# SAM9X60 device description
Architecture: ARM926EJS; Family: SAM9; Series: SAM9X
Registers are 32-bit, read-write, no defined reset value unless marked. A register's access mark holds for its fields unless they carry their own. Offsets are from the block's base; [hi:lo] are bit positions; lines under a group give offsets from that group; {n}, {i} and the like mark numbered series.

## PMECC — Programmable Multibit Error Correction Code Controller
Instances: PMECC 0xFFFFE000
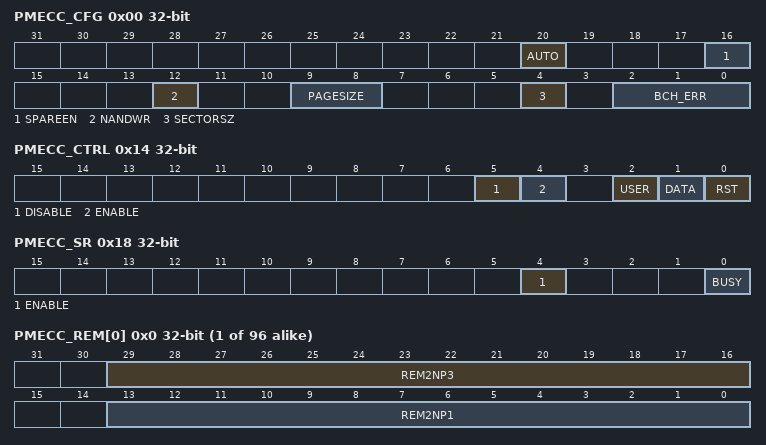
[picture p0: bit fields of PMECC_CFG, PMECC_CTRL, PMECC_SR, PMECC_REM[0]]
0x00 PMECC_CFG — PMECC Configuration Register
  [20] AUTO — Automatic Mode Enable
  [16] SPAREEN — Spare Enable
  [12] NANDWR — NAND Write Access
  [9:8] PAGESIZE — Number of Sectors in the Page
    0=PAGESIZE_1SEC (1 sector for main area (512 or 1024 bytes)); 1=PAGESIZE_2SEC (2 sectors for main area (1024 or 2048 bytes)); 2=PAGESIZE_4SEC (4 sectors for main area (2048 or 4096 bytes)); 3=PAGESIZE_8SEC (8 errors for main area (4096 or 8192 bytes))
  [4] SECTORSZ — Sector Size
  [2:0] BCH_ERR — Error Correct Capability
    0=2 errors; 1=4 errors; 2=8 errors; 3=12 errors; 4=24 errors
0x04 PMECC_SAREA — PMECC Spare Area Size Register
  [8:0] SPARESIZE — Spare Area Size
0x08 PMECC_SADDR — PMECC Start Address Register
  [8:0] STARTADDR — ECC Area Start Address (byte oriented address)
0x0C PMECC_EADDR — PMECC End Address Register
  [8:0] ENDADDR — ECC Area End Address (byte oriented address)
0x10 PMECC_CLK — PMECC Clock Control Register
  [2:0] CLKCTRL — Clock Control Register
0x14 PMECC_CTRL wo — PMECC Control Register
  [5] DISABLE — PMECC Module Disable
  [4] ENABLE — PMECC Module Enable
  [2] USER — Start a User Mode Phase
  [1] DATA — Start a Data Phase
  [0] RST — Reset the PMECC Module
0x18 PMECC_SR ro — PMECC Status Register
  [4] ENABLE — PMECC Module Status
  [0] BUSY — The Kernel of the PMECC is Busy
0x1C PMECC_IER wo — PMECC Interrupt Enable register
  [0] ERRIE — Error Interrupt Enable
0x20 PMECC_IDR wo — PMECC Interrupt Disable Register
  [0] ERRID — Error Interrupt Disable
0x24 PMECC_IMR ro — PMECC Interrupt Mask Register
  [0] ERRIM — Error Interrupt Mask
0x28 PMECC_ISR ro — PMECC Interrupt Status Register
  [7:0] ERRIS — Error Interrupt Status
{0x40+0x40*i} PMECC_ECC[{i}] (i=0..7) group
  {0x0+4j} PMECC_ECC[{j}] (j=0..10) ro — PMECC ECC 0 Register (sec_num = 0)
    [31:0] ECC — BCH Redundancy
{0x240+0x40*i} PMECC_REM[{i}] (i=0..7) group
  {0x0+4j} PMECC_REM[{j}] (j=0..11) ro — PMECC REM 0 Register (sec_num = 0)
    [29:16] REM2NP3 — BCH Remainder 2 * N + 3
    [13:0] REM2NP1 — BCH Remainder 2 * N + 1
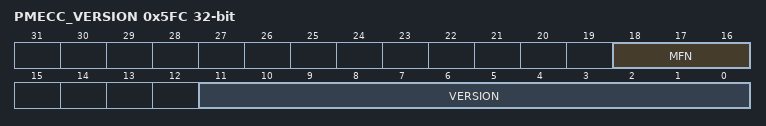
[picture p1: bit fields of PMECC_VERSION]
0x5FC PMECC_VERSION ro
  [18:16] MFN — Metal Fix Number
  [11:0] VERSION — Version of the Hardware Module

## PMERRLOC — Programmable Multibit ECC Error Location
Instances: PMERRLOC 0xFFFFE600
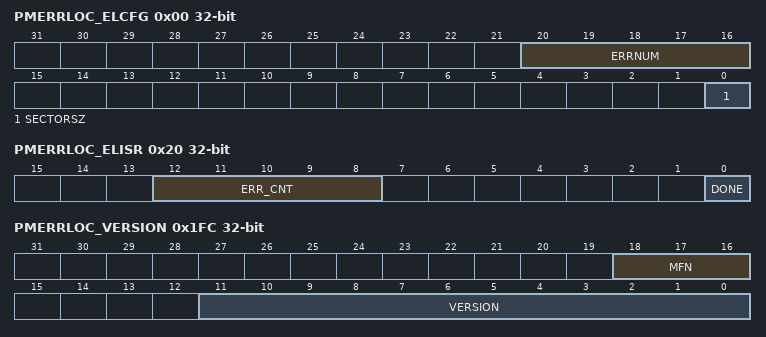
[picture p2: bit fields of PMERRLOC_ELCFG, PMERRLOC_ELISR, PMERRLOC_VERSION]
0x00 PMERRLOC_ELCFG — Configuration Register
  [20:16] ERRNUM — Number of Errors
  [0] SECTORSZ — Sector Size
0x04 PMERRLOC_ELPRIM ro — Primitive Register
  [15:0] PRIMITIV — Primitive Polynomial
0x08 PMERRLOC_ELEN — Enable Register
  [13:0] ENINIT — Initial Number of Bits in the Codeword
0x0C PMERRLOC_ELDIS — Disable Register
  [0] DIS — Disable Error Location Engine
0x10 PMERRLOC_ELSR — Status Register
  [0] BUSY — Error Location Engine Busy
0x14 PMERRLOC_ELIER wo — Interrupt Enable Register
  [0] DONE — Computation Terminated Interrupt Enable
0x18 PMERRLOC_ELIDR wo — Interrupt Disable Register
  [0] DONE — Computation Terminated Interrupt Disable
0x1C PMERRLOC_ELIMR ro — Interrupt Mask Register
  [0] DONE — Computation Terminated Interrupt Mask
0x20 PMERRLOC_ELISR ro — Interrupt Status Register
  [12:8] ERR_CNT — Error Counter Value
  [0] DONE — Computation Terminated Interrupt Status
0x28 PMERRLOC_SIGMA0 ro — SIGMA0 Register
  [13:0] SIGMA0 — Coefficient of Degree 0 in the SIGMA Polynomial
{0x28+4i} PMERRLOC_SIGMA{i} (i=1..23) — SIGMA1 Register
  [13:0] SIGMA{i} — Coefficient of Degree x in the SIGMA Polynomial.
0x88 PMERRLOC_SIGMA24 — SIGMA24 Register
  [13:0] SIGMA24 — Coefficient of Degree x in the SIGMA Polynomial.
{0x8C+4i} PMERRLOC_EL[{i}] (i=0..23) ro — Error Location 0 Register
  [13:0] ERRLOCN — Error Position within the Set {sector area, spare area}.
0x1FC PMERRLOC_VERSION ro — Version Register
  [18:16] MFN — Metal Fix Number
  [11:0] VERSION — Version of the Hardware Module
